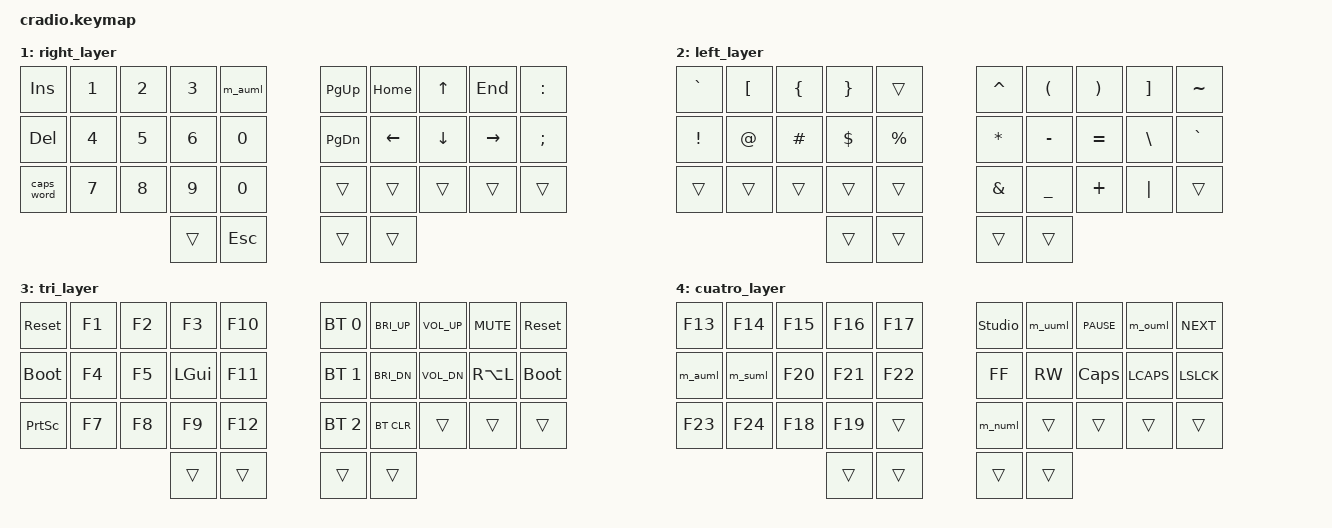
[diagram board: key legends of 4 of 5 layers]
// Copyright (c) 2022 The ZMK Contributors
// SPDX-License-Identifier: MIT

#include <behaviors.dtsi>
#include <dt-bindings/zmk/keys.h>
#include <dt-bindings/zmk/bt.h>
// https://zmk.dev/docs/codes
// https://de.wikipedia.org/wiki/Tastaturbelegung_US-International#/media/Datei:KB_US-International.svg
// https://keymap-drawer.streamlit.app/?zmk_url=https%3A%2F%2Fgithub.com%2Fmknj%2Fzmk-config%2Fblob%2Fmain%2Fconfig%2Fcradio.keymap

// Home row mods macro
#define HRML(k1,k2,k3,k4) &ht LSHFT k1  &ht LALT k2  &ht LCTRL k3  &ht LGUI k4
#define HRMR(k1,k2,k3,k4) &ht RGUI k1  &ht RCTRL k2  &ht RALT k3  &ht RSHFT k4

/ {
    behaviors {
        ht: hold_tap {
            compatible = "zmk,behavior-hold-tap";
            #binding-cells = <2>;
            flavor = "tap-preferred";
            tapping-term-ms = <220>;
            quick-tap-ms = <150>;
            global-quick-tap;
            require-prior-idle-ms = <100>;
            bindings = <&kp>, <&kp>;
        };
    };

    conditional_layers {
        compatible = "zmk,conditional-layers";
        tri_layer {
            if-layers = <1 2>;
            then-layer = <3>;
        };
    };
    macros {
        m_auml: m_auml {
            compatible = "zmk,behavior-macro";
            #binding-cells = <0>;
            bindings
                = <&macro_press &kp LSHFT>
                , <&macro_tap &kp SQT>
                , <&macro_release &kp LSHFT>
                , <&macro_tap &kp A>
                ;
        };
        m_uuml: u_auml {
            compatible = "zmk,behavior-macro";
            #binding-cells = <0>;
            bindings
                = <&macro_press &kp LSHFT>
                , <&macro_tap &kp SQT>
                , <&macro_release &kp LSHFT>
                , <&macro_tap &kp U>
                ;
        };
        m_ouml: m_ouml {
            compatible = "zmk,behavior-macro";
            #binding-cells = <0>;
            bindings
                = <&macro_press &kp LSHFT>
                , <&macro_tap &kp SQT>
                , <&macro_release &kp LSHFT>
                , <&macro_tap &kp O>
                ;
        };
        m_suml: m_suml {
            compatible = "zmk,behavior-macro";
            #binding-cells = <0>;
            bindings
                = <&macro_press &kp RALT>
                , <&macro_tap &kp S>
                , <&macro_release &kp RALT>
                ;
        };
        m_numl: m_numl {
            compatible = "zmk,behavior-macro";
            #binding-cells = <0>;
            bindings
                = <&macro_tap &kp TILDE>
                , <&macro_tap &kp N>
                ;
        };
    }
    keymap {
        compatible = "zmk,keymap";
        default_layer {
            bindings = <
        //╭──────────┬──────────┬──────────┬──────────┬──────────╮   ╭──────────┬──────────┬──────────┬──────────┬──────────╮
        //│  Q       │  W       │  E       │  R       │  T       │   │  Y       │  U       │  I       │  O       │  P       │
            &kp Q      &kp W      &kp E      &kp R      &kp T          &kp Y      &kp U      &kp I      &kp O      &kp P
        //├──────────┼──────────┼──────────┼──────────┼──────────┤   ├──────────┼──────────┼──────────┼──────────┼──────────┤
        //│  A       │  S       │  D       │  F       │  G       │   │  H       │  J       │  K       │  L       │ ' "      │
            HRML(A,        S,         D,         F)     &kp G          &kp H      HRMR(J,        K,         L,        SQT)
        //├──────────┼──────────┼──────────┼──────────┼──────────┤   ├──────────┼──────────┼──────────┼──────────┼──────────┤
        //│  Z       │  X       │  C       │  V       │  B       │   │  N       │  M       │ , <      │ . >      │ / ?      │
          &ht LSHFT Z  &kp X      &kp C      &kp V      &kp B          &kp N      &kp M      &kp COMMA  &kp DOT  &ht RSHFT FSLH
        //╰──────────┴──────────┴──────────┼──────────┼──────────┤   ├──────────┼──────────┼──────────┴──────────┴──────────╯
                                            &lt 2 TAB   &kp SPACE    &lt 4 ENTER &lt 1 BSPC
        //                                 ╰──────────┴──────────╯   ╰──────────┴──────────╯
            >;
        };

        right_layer {
            bindings = <
        //╭──────────┬──────────┬──────────┬──────────┬──────────╮   ╭──────────┬──────────┬──────────┬──────────┬──────────╮
        //│ INSERT   │  1       │  2       │  3       │    Ä     │   │ PAGE UP  │ HOME     │ UP       │ END      │  :       │
            &kp INS    &kp N1     &kp N2     &kp N3     &m_auml        &kp PG_UP  &kp HOME   &kp UP     &kp END    &kp COLON
        //├──────────┼──────────┼──────────┼──────────┼──────────┤   ├──────────┼──────────┼──────────┼──────────┼──────────┤
        //│ DELETE   │  4       │  5       │  6       │  0       │   │ PAGE DN  │ LEFT     │ DOWN     │ RIGHT    │  ;       │
            &kp DEL    &kp N4     &kp N5     &kp N6     &kp N0         &kp PG_DN  &kp LEFT   &kp DOWN   &kp RIGHT   &kp SEMI
        //├──────────┼──────────┼──────────┼──────────┼──────────┤   ├──────────┼──────────┼──────────┼──────────┼──────────┤
        //│ CAPS     │  7       │  8       │  9       │  0       │   │          │          │          │          │          │
           &caps_word  &kp N7     &kp N8     &kp N9     &kp N0         &trans     &trans     &trans     &trans     &trans
        //╰──────────┴──────────┴──────────┼──────────┼──────────┤   ├──────────┼──────────┼──────────┴──────────┴──────────╯
                                             &trans     &kp ESC        &trans     &trans
        //                                 ╰──────────┴──────────╯   ╰──────────┴──────────╯
            >;
        };

        left_layer {
            bindings = <
        //╭──────────┬──────────┬──────────┬──────────┬──────────╮   ╭──────────┬──────────┬──────────┬──────────┬──────────╮
        //│  `       │  [       │  {       │  }       │          │   │  ^       │  (       │  )       │  ]       │  ~       │
            &kp GRAVE  &kp LBKT   &kp LBRC   &kp RBRC   &trans         &kp CARET  &kp LPAR   &kp RPAR   &kp RBKT   &kp TILDE
        //├──────────┼──────────┼──────────┼──────────┼──────────┤   ├──────────┼──────────┼──────────┼──────────┼──────────┤
        //│  !       │  @       │  #       │  $       │  %       │   │  *       │  -       │  =       │  \       │  `       │
            &kp EXCL   &kp AT     &kp HASH   &kp DLLR   &kp PRCNT      &kp ASTRK  &kp MINUS  &kp EQUAL  &kp BSLH   &kp GRAVE
        //├──────────┼──────────┼──────────┼──────────┼──────────┤   ├──────────┼──────────┼──────────┼──────────┼──────────┤
        //│          │          │          │          │          │   │  &       │  _       │  +       │  │       │          │
            &trans     &trans     &trans     &trans     &trans         &kp AMPS   &kp UNDER  &kp PLUS   &kp PIPE   &trans
        //╰──────────┴──────────┴──────────┼──────────┼──────────┤   ├──────────┼──────────┼──────────┴──────────┴──────────╯
                                             &trans     &trans         &trans     &trans
        //                                 ╰──────────┴──────────╯   ╰──────────┴──────────╯
            >;
        };
        tri_layer {
            bindings = <
        //╭──────────┬──────────┬──────────┬──────────┬──────────╮   ╭──────────┬──────────┬──────────┬──────────┬──────────╮
        //│ RESET    │          │          │          │          │   │          │          │          │          │  RESET   │
           &sys_reset  &kp F1     &kp F2     &kp F3    &kp F10       &bt BT_SEL 0 &kp C_BRI_UP &kp  C_VOL_UP &kp C_MUTE   &sys_reset
        //├──────────┼──────────┼──────────┼──────────┼──────────┤   ├──────────┼──────────┼──────────┼──────────┼──────────┤
        //│BOOTLOADER│          │          │          │          │   │          │          │          │          │BOOTLOADER│
          &bootloader  &kp F4     &kp F5     &kp LGUI  &kp F11       &bt BT_SEL 1  &kp C_BRI_DN &kp C_VOL_DN       &kp RA(L) &bootloader
        //├──────────┼──────────┼──────────┼──────────┼──────────┤   ├──────────┼──────────┼──────────┼──────────┼──────────┤
        //│          │          │          │          │          │   │          │          │          │          │          │
           &kp PSCRN   &kp F7     &kp F8     &kp F9     &kp F12      &bt BT_SEL 2 &bt BT_CLR &trans     &trans     &trans
        //╰──────────┴──────────┴──────────┼──────────┼──────────┤   ├──────────┼──────────┼──────────┴──────────┴──────────╯
                                             &trans     &trans         &trans     &trans
        //                                 ╰──────────┴──────────╯   ╰──────────┴──────────╯
            >;
        };
        cuatro_layer {
            bindings = <
        //╭──────────┬──────────┬──────────┬──────────┬──────────╮   ╭──────────┬──────────┬──────────┬──────────┬──────────╮
        //│          │          │          │          │          │   │          │          │          │          │          │
            &kp F13     &kp F14    &kp F15    &kp F16    &kp F17   &studio_unlock &m_uuml  &kp C_PAUSE  &m_ouml  &kp C_NEXT
        //├──────────┼──────────┼──────────┼──────────┼──────────┤   ├──────────┼──────────┼──────────┼──────────┼──────────┤
        //│BOOTLOADER│          │          │          │          │   │          │          │          │          │BOOTLOADER│
             &m_auml    &m_suml     &kp F20   &kp F21    &kp F22       &kp C_FF   &kp C_RW &kp CAPS    &kp LCAPS  &kp LSLCK
        //├──────────┼──────────┼──────────┼──────────┼──────────┤   ├──────────┼──────────┼──────────┼──────────┼──────────┤
        //│          │          │          │          │          │   │          │          │          │          │          │
           &kp F23   &kp F24       &kp F18    &kp F19     &trans       &m_numl   &trans      &trans     &trans     &trans
        //╰──────────┴──────────┴──────────┼──────────┼──────────┤   ├──────────┼──────────┼──────────┴──────────┴──────────╯
                                             &trans     &trans         &trans     &trans
        //                                 ╰──────────┴──────────╯   ╰──────────┴──────────╯
            >;
        };
    };
};
